# ARMCM0P register map
Vendor: ARM Ltd.; Series: ARM Cortex M0+; File version: 1.0
ARM 32-bit Cortex-M0+ based device.
CPU: CM0+ r0p0, little endian, no MPU, no FPU, 2 interrupt priority bits
Registers are 32-bit, read-write, reset 0x0 unless marked. A register's access mark holds for its fields unless they carry their own. Offsets are from the block's base; lines under a group give offsets from that group; [hi:lo] are bit positions; {n}, {i} and the like mark numbered series; 'fields as' and 'values as' point back to an identical list; <NAME> marks a mode.

## Memory map
0xE000E000 SCB — System Control Block

## SCB — System Control Block
Base 0xE000E000
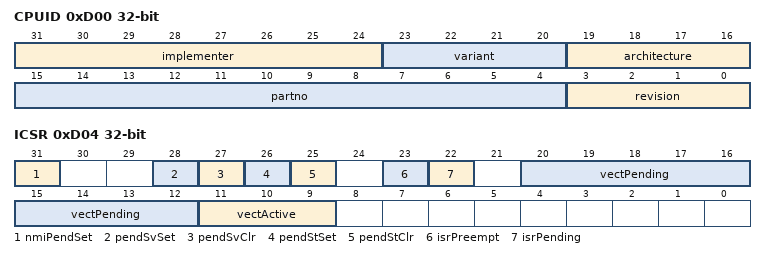
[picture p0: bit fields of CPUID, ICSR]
0xD00 CPUID ro — Provides identification information for the processor
  [31:24] implementer, [23:20] variant, [19:16] architecture, [15:4] partno, [3:0] revision
0xD04 ICSR — Interrupt Control State Register
  [31] nmiPendSet, [28] pendSvSet, [27] pendSvClr wo, [26] pendStSet, [25] pendStClr wo, [23] isrPreempt ro, [22] isrPending ro, [20:12] vectPending ro, [11:9] vectActive ro
0xD08 VTOR — Vector Table Offset Register
  [31:7] tblOff
0xD0C AIRCR — Application Interrupt and Reset Control Register
  [31:16] vectKey wo
    0x5FA=Vector Key. The value 0x05FA must be written to this register, otherwise the register write is UNPREDICTABLE.
  [15] endianness ro
    0=littleEndian; 1=bigEndian
  [16:15] sysResetReq wo
  [15] vectClrActive wo
0xD10 SCR — System Control Register
0xD14 CCR ro — Configuration and Control Register
0xD1C SHPR2 — System Handler Priority Register 2
0xD20 SHPR3 — System Handler Priority Register 3
0xD24 SHCSR — System Handler Control and State Register
0xD30 DFSR — Default Fault Status Register

## Licence text in the file
ARM Limited (ARM) is supplying this software for use with Cortex-M processor based microcontroller, but can be equally used for other suitable processor architectures. This file can be freely distributed. Modifications to this file shall be clearly marked. . THIS SOFTWARE IS PROVIDED "AS IS". NO WARRANTIES, WHETHER EXPRESS, IMPLIED. OR STATUTORY, INCLUDING, BUT NOT LIMITED TO, IMPLIED WARRANTIES OF. MERCHANTABILITY AND FITNESS FOR A PARTICULAR PURPOSE APPLY TO THIS SOFTWARE. ARM SHALL NOT, IN ANY CIRCUMSTANCES, BE LIABLE FOR SPECIAL, INCIDENTAL, OR. CONSEQUENTIAL DAMAGES, FOR ANY REASON WHATSOEVER.

## Notices in the file
Copyright (C) 2012 - 2018 Arm Limited. All rights reserved.
Purpose: System Viewer Description (SVD) Example (Schema Version 1.1)
This is a description of a none-existent and incomplete device
for demonstration purposes only.
Redistribution and use in source and binary forms, with or without
modification, are permitted provided that the following conditions are met:
- Redistributions of source code must retain the above copyright
notice, this list of conditions and the following disclaimer.
- Redistributions in binary form must reproduce the above copyright
notice, this list of conditions and the following disclaimer in the
documentation and/or other materials provided with the distribution.
- Neither the name of ARM nor the names of its contributors may be used
to endorse or promote products derived from this software without
specific prior written permission.
THIS SOFTWARE IS PROVIDED BY THE COPYRIGHT HOLDERS AND CONTRIBUTORS "AS IS"
AND ANY EXPRESS OR IMPLIED WARRANTIES, INCLUDING, BUT NOT LIMITED TO, THE
ARE DISCLAIMED. IN NO EVENT SHALL COPYRIGHT HOLDERS AND CONTRIBUTORS BE
LIABLE FOR ANY DIRECT, INDIRECT, INCIDENTAL, SPECIAL, EXEMPLARY, OR
CONSEQUENTIAL DAMAGES (INCLUDING, BUT NOT LIMITED TO, PROCUREMENT OF
SUBSTITUTE GOODS OR SERVICES; LOSS OF USE, DATA, OR PROFITS; OR BUSINESS
INTERRUPTION) HOWEVER CAUSED AND ON ANY THEORY OF LIABILITY, WHETHER IN
CONTRACT, STRICT LIABILITY, OR TORT (INCLUDING NEGLIGENCE OR OTHERWISE)
ARISING IN ANY WAY OUT OF THE USE OF THIS SOFTWARE, EVEN IF ADVISED OF THE
POSSIBILITY OF SUCH DAMAGE.
